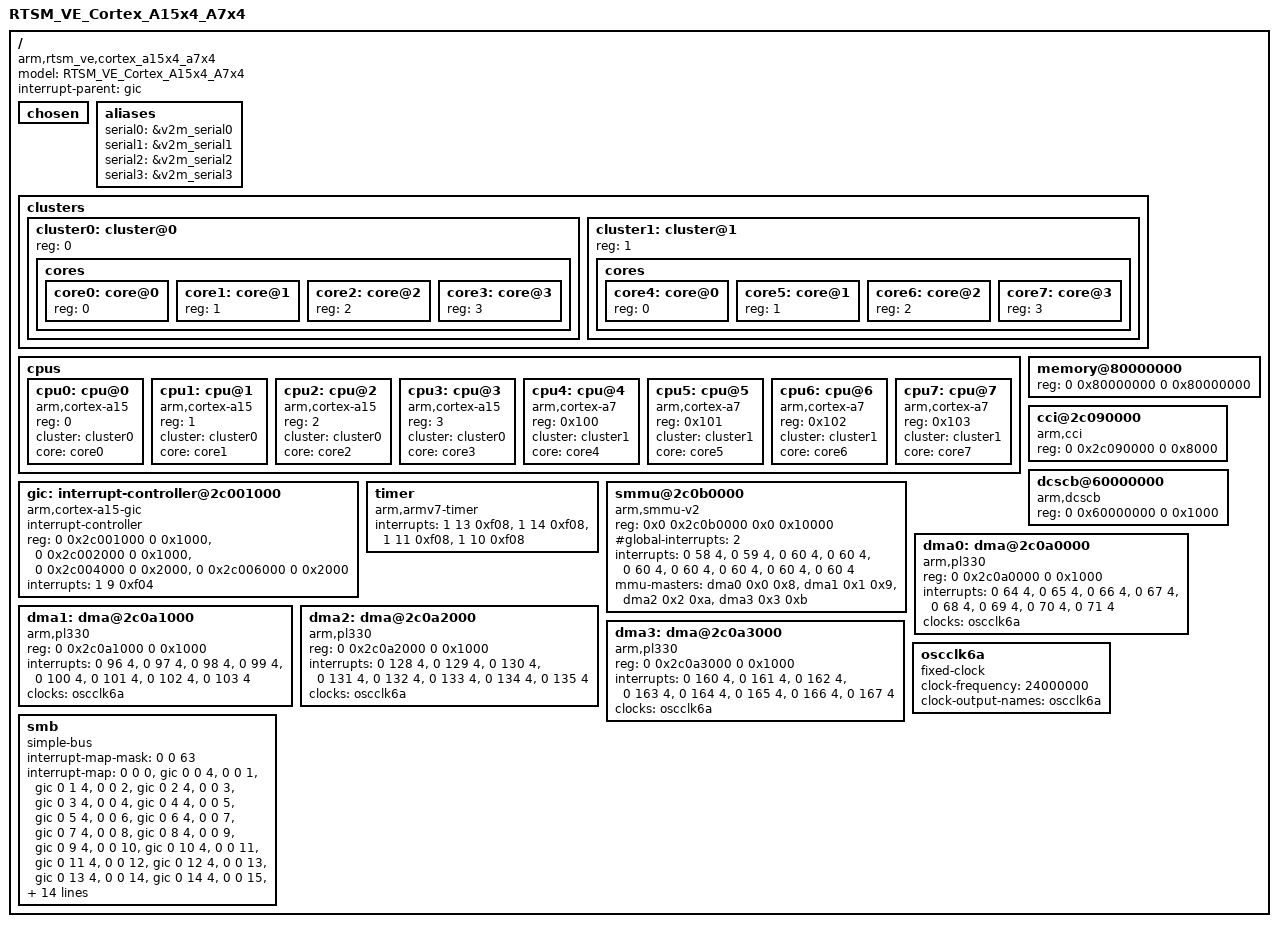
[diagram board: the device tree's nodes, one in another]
/*
 * ARM Ltd. Fast Models
 *
 * Versatile Express (VE) system model
 * ARMCortexA7x4CT
 * ARMCortexA15x4CT
 *
 * RTSM_VE_Cortex_A15x4_A7x4.lisa
 */

/dts-v1/;

/ {
	model = "RTSM_VE_Cortex_A15x4_A7x4";
	compatible = "arm,rtsm_ve,cortex_a15x4_a7x4", "arm,vexpress";
	interrupt-parent = <&gic>;
	#address-cells = <2>;
	#size-cells = <2>;

	chosen { };

	aliases {
		serial0 = &v2m_serial0;
		serial1 = &v2m_serial1;
		serial2 = &v2m_serial2;
		serial3 = &v2m_serial3;
	};

	clusters {
		#address-cells = <1>;
		#size-cells = <0>;

		cluster0: cluster@0 {
			reg = <0>;
			cores {
				#address-cells = <1>;
				#size-cells = <0>;

				core0: core@0 {
					reg = <0>;
				};

				core1: core@1 {
					reg = <1>;
				};

				core2: core@2 {
					reg = <2>;
				};

				core3: core@3 {
					reg = <3>;
				};
			};
		};

		cluster1: cluster@1 {
			reg = <1>;
			cores {
				#address-cells = <1>;
				#size-cells = <0>;

				core4: core@0 {
					reg = <0>;
				};

				core5: core@1 {
					reg = <1>;
				};

				core6: core@2 {
					reg = <2>;
				};

				core7: core@3 {
					reg = <3>;
				};
			};
		};
	};

	cpus {
		#address-cells = <1>;
		#size-cells = <0>;

		cpu0: cpu@0 {
			device_type = "cpu";
			compatible = "arm,cortex-a15";
			reg = <0>;
			cluster = <&cluster0>;
			core = <&core0>;
		};

		cpu1: cpu@1 {
			device_type = "cpu";
			compatible = "arm,cortex-a15";
			reg = <1>;
			cluster = <&cluster0>;
			core = <&core1>;
		};

		cpu2: cpu@2 {
			device_type = "cpu";
			compatible = "arm,cortex-a15";
			reg = <2>;
			cluster = <&cluster0>;
			core = <&core2>;
		};

		cpu3: cpu@3 {
			device_type = "cpu";
			compatible = "arm,cortex-a15";
			reg = <3>;
			cluster = <&cluster0>;
			core = <&core3>;
		};

		cpu4: cpu@4 {
			device_type = "cpu";
			compatible = "arm,cortex-a7";
			reg = <0x100>;
			cluster = <&cluster1>;
			core = <&core4>;
		};

		cpu5: cpu@5 {
			device_type = "cpu";
			compatible = "arm,cortex-a7";
			reg = <0x101>;
			cluster = <&cluster1>;
			core = <&core5>;
		};

		cpu6: cpu@6 {
			device_type = "cpu";
			compatible = "arm,cortex-a7";
			reg = <0x102>;
			cluster = <&cluster1>;
			core = <&core6>;
		};

		cpu7: cpu@7 {
			device_type = "cpu";
			compatible = "arm,cortex-a7";
			reg = <0x103>;
			cluster = <&cluster1>;
			core = <&core7>;
		};
	};

	memory@80000000 {
		device_type = "memory";
		reg = <0 0x80000000 0 0x80000000>;
	};

	gic: interrupt-controller@2c001000 {
		compatible = "arm,cortex-a15-gic", "arm,cortex-a9-gic";
		#interrupt-cells = <3>;
		#address-cells = <0>;
		interrupt-controller;
		reg = <0 0x2c001000 0 0x1000>,
		      <0 0x2c002000 0 0x1000>,
		      <0 0x2c004000 0 0x2000>,
		      <0 0x2c006000 0 0x2000>;
		interrupts = <1 9 0xf04>;
	};

	cci@2c090000 {
		compatible = "arm,cci";
		reg = <0 0x2c090000 0 0x8000>;
	};

	dcscb@60000000 {
		compatible = "arm,dcscb";
		reg = <0 0x60000000 0 0x1000>;
	};

	timer {
		compatible = "arm,armv7-timer";
		interrupts = <1 13 0xf08>,
			     <1 14 0xf08>,
			     <1 11 0xf08>,
			     <1 10 0xf08>;
	};
/*
	smmu@2c0b0000 {
                compatible = "arm,smmu-v1";
                reg = <0x0 0x2c0b0000 0x0 0x10000>;
                #global-interrupts = <4>;
                interrupts = <0 56 4>,
                             <0 57 4>,
			     <0 58 4>,
			     <0 59 4>,
                             <0 60 4>;
                mmu-masters = <&dma0 0x0 0x8>,
                              <&dma1 0x1 0x9>,
                              <&dma2 0x2 0xa>,
                              <&dma3 0x3 0xb>;
        };
*/
	smmu@2c0b0000 {
                compatible = "arm,smmu-v2";
                reg = <0x0 0x2c0b0000 0x0 0x10000>;
                #global-interrupts = <2>;
                interrupts = <0 58 4>,
                             <0 59 4>,
                             <0 60 4>,
                             <0 60 4>,
                             <0 60 4>,
                             <0 60 4>,
                             <0 60 4>,
                             <0 60 4>,
                             <0 60 4>;
                mmu-masters = <&dma0 0x0 0x8>,
                              <&dma1 0x1 0x9>,
                              <&dma2 0x2 0xa>,
                              <&dma3 0x3 0xb>;
        };

	dma0: dma@2c0a0000 {
		compatible = "arm,pl330", "arm,primecell";
		reg = <0 0x2c0a0000 0 0x1000>;
		interrupts = <0 64 4>,
			     <0 65 4>,
			     <0 66 4>,
			     <0 67 4>,
			     <0 68 4>,
			     <0 69 4>,
			     <0 70 4>,
			     <0 71 4>;
		#dma-cells = <1>;
		#stream-id-cells = <2>;
		clocks = <&oscclk6a>;
		clock-names = "apb_pclk";
	};

	dma1: dma@2c0a1000 {
		compatible = "arm,pl330", "arm,primecell";
		reg = <0 0x2c0a1000 0 0x1000>;
		interrupts = <0 96 4>,
			     <0 97 4>,
			     <0 98 4>,
			     <0 99 4>,
			     <0 100 4>,
			     <0 101 4>,
			     <0 102 4>,
			     <0 103 4>;
		#dma-cells = <1>;
		#stream-id-cells = <2>;
		clocks = <&oscclk6a>;
		clock-names = "apb_pclk";
	};

	dma2: dma@2c0a2000 {
		compatible = "arm,pl330", "arm,primecell";
		reg = <0 0x2c0a2000 0 0x1000>;
		interrupts = <0 128 4>,
			     <0 129 4>,
			     <0 130 4>,
			     <0 131 4>,
			     <0 132 4>,
			     <0 133 4>,
			     <0 134 4>,
			     <0 135 4>;
		#dma-cells = <1>;
		#stream-id-cells = <2>;
		clocks = <&oscclk6a>;
		clock-names = "apb_pclk";
	};

	dma3: dma@2c0a3000 {
		compatible = "arm,pl330", "arm,primecell";
		reg = <0 0x2c0a3000 0 0x1000>;
		interrupts = <0 160 4>,
			     <0 161 4>,
			     <0 162 4>,
			     <0 163 4>,
			     <0 164 4>,
			     <0 165 4>,
			     <0 166 4>,
			     <0 167 4>;
		#dma-cells = <1>;
		#stream-id-cells = <2>;
		clocks = <&oscclk6a>;
		clock-names = "apb_pclk";
	};

	oscclk6a: oscclk6a {
		/* Reference 24MHz clock */
		compatible = "fixed-clock";
		#clock-cells = <0>;
		clock-frequency = <24000000>;
		clock-output-names = "oscclk6a";
	};

	smb {
		compatible = "simple-bus";

		#address-cells = <2>;
		#size-cells = <1>;
		ranges = <0 0 0 0x08000000 0x04000000>,
			 <1 0 0 0x14000000 0x04000000>,
			 <2 0 0 0x18000000 0x04000000>,
			 <3 0 0 0x1c000000 0x04000000>,
			 <4 0 0 0x0c000000 0x04000000>,
			 <5 0 0 0x10000000 0x04000000>;

		#interrupt-cells = <1>;
		interrupt-map-mask = <0 0 63>;
		interrupt-map = <0 0  0 &gic 0  0 4>,
				<0 0  1 &gic 0  1 4>,
				<0 0  2 &gic 0  2 4>,
				<0 0  3 &gic 0  3 4>,
				<0 0  4 &gic 0  4 4>,
				<0 0  5 &gic 0  5 4>,
				<0 0  6 &gic 0  6 4>,
				<0 0  7 &gic 0  7 4>,
				<0 0  8 &gic 0  8 4>,
				<0 0  9 &gic 0  9 4>,
				<0 0 10 &gic 0 10 4>,
				<0 0 11 &gic 0 11 4>,
				<0 0 12 &gic 0 12 4>,
				<0 0 13 &gic 0 13 4>,
				<0 0 14 &gic 0 14 4>,
				<0 0 15 &gic 0 15 4>,
				<0 0 16 &gic 0 16 4>,
				<0 0 17 &gic 0 17 4>,
				<0 0 18 &gic 0 18 4>,
				<0 0 19 &gic 0 19 4>,
				<0 0 20 &gic 0 20 4>,
				<0 0 21 &gic 0 21 4>,
				<0 0 22 &gic 0 22 4>,
				<0 0 23 &gic 0 23 4>,
				<0 0 24 &gic 0 24 4>,
				<0 0 25 &gic 0 25 4>,
				<0 0 26 &gic 0 26 4>,
				<0 0 27 &gic 0 27 4>,
				<0 0 28 &gic 0 28 4>,
				<0 0 29 &gic 0 29 4>,
				<0 0 30 &gic 0 30 4>,
				<0 0 31 &gic 0 31 4>,
				<0 0 32 &gic 0 32 4>,
				<0 0 33 &gic 0 33 4>,
				<0 0 34 &gic 0 34 4>,
				<0 0 35 &gic 0 35 4>,
				<0 0 36 &gic 0 36 4>,
				<0 0 37 &gic 0 37 4>,
				<0 0 38 &gic 0 38 4>,
				<0 0 39 &gic 0 39 4>,
				<0 0 40 &gic 0 40 4>,
				<0 0 41 &gic 0 41 4>,
				<0 0 42 &gic 0 42 4>;

		/include/ "rtsm_ve-motherboard.dtsi"
	};
};
